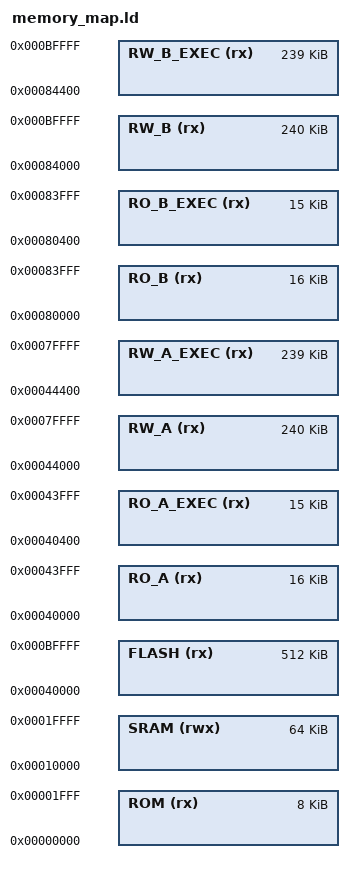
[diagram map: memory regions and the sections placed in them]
MEMORY
{
  ROM   (rx)  : ORIGIN = 0x00000000, LENGTH = 8K
  SRAM  (rwx) : ORIGIN = 0x00010000, LENGTH = 64K
  FLASH (rx)  : ORIGIN = 0x00040000, LENGTH = 512K

  RO_A  (rx)  : ORIGIN = 0x00040000, LENGTH = 16K
  RW_A  (rx)  : ORIGIN = 0x00044000, LENGTH = 240K
  RO_B  (rx)  : ORIGIN = 0x00080000, LENGTH = 16K
  RW_B  (rx)  : ORIGIN = 0x00084000, LENGTH = 240K

  /* sizeof(SignedHeader) == 0x400 */
  RO_A_EXEC (rx) : ORIGIN = 0x00040400, LENGTH = 16K - 0x400
  RW_A_EXEC (rx) : ORIGIN = 0x00044400, LENGTH = 240K - 0x400
  RO_B_EXEC (rx) : ORIGIN = 0x00080400, LENGTH = 16K - 0x400
  RW_B_EXEC (rx) : ORIGIN = 0x00084400, LENGTH = 240K - 0x400
}
